# APM32F103xx register map
File version: 1.0
CPU: CM3 r2p1, little endian, no MPU, no FPU, 4 interrupt priority bits
Registers are 32-bit, read-write, reset 0x0 unless marked. A register's access mark holds for its fields unless they carry their own. Offsets are from the block's base; [hi:lo] are bit positions; lines under a group give offsets from that group; {n}, {i} and the like mark numbered series.

## ADC1 — Analog to digital converter
Base 0x40012400
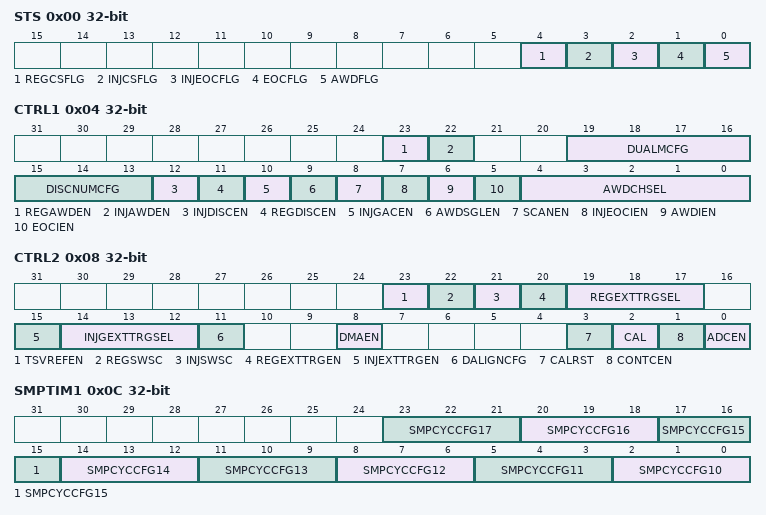
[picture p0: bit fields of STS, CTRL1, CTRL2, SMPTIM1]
0x00 STS — status register
  [4] REGCSFLG — Regular channel start flag
  [3] INJCSFLG — Injected channel start flag
  [2] INJEOCFLG — Injected channel end of conversion
  [1] EOCFLG — Regular channel end of conversion
  [0] AWDFLG — Analog watchdog flag
0x04 CTRL1 — control register 1
  [23] REGAWDEN — Analog watchdog enable on regular channels
  [22] INJAWDEN — Analog watchdog enable on injected channels
  [19:16] DUALMCFG — Dual mode selection
  [15:13] DISCNUMCFG — Discontinuous mode channel count
  [12] INJDISCEN — Discontinuous mode on injected channels
  [11] REGDISCEN — Discontinuous mode on regular channels
  [10] INJGACEN — Automatic injected group conversion
  [9] AWDSGLEN — Enable the watchdog on a single channel in scan mode
  [8] SCANEN — Scan mode
  [7] INJEOCIEN — Interrupt enable for injected channels
  [6] AWDIEN — Analog watchdog interrupt enable
  [5] EOCIEN — Interrupt enable for EOC
  [4:0] AWDCHSEL — Analog watchdog channel select bits
0x08 CTRL2 — control register 2
  [23] TSVREFEN — Temperature sensor and VREFINT enable
  [22] REGSWSC — Start conversion of regular channels
  [21] INJSWSC — Start conversion of injected channels
  [20] REGEXTTRGEN — External trigger conversion mode for regular channels
  [19:17] REGEXTTRGSEL — External event select for regular group
  [15] INJEXTTRGEN — External trigger conversion mode for injected channels
  [14:12] INJGEXTTRGSEL — External event select for injected group
  [11] DALIGNCFG — Data alignment
  [8] DMAEN — Direct memory access mode
  [3] CALRST — Reset calibration
  [2] CAL — A/D calibration
  [1] CONTCEN — Continuous conversion
  [0] ADCEN — A/D converter ON / OFF
0x0C SMPTIM1 — sample time register 1
  [3n-28:3n-30] SMPCYCCFG{n} (n=10..17) — Channel {n} sample time selection
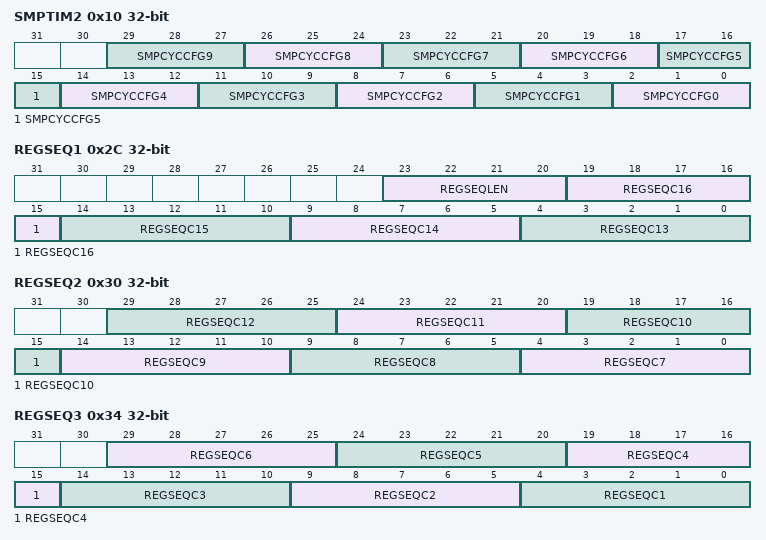
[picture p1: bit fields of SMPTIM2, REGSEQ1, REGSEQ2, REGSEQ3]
0x10 SMPTIM2 — sample time register 2
  [3n+2:3n] SMPCYCCFG{n} (n=0..9) — Channel {n} sample time selection
{0x10+4i} INJDOF{i} (i=1..4) — injected channel data offset register {i}
  [11:0] INJDOF{i} — Data offset for injected channel {i}
0x24 AWDHT reset 0xFFF — watchdog higher threshold register
  [11:0] AWDHT — Analog watchdog higher threshold
0x28 AWDLT — watchdog lower threshold register
  [11:0] AWDLT — Analog watchdog lower threshold
0x2C REGSEQ1 — regular sequence register 1
  [23:20] REGSEQLEN — Regular channel sequence length
  [5n-61:5n-65] REGSEQC{n} (n=13..16) — {n}th conversion in regular sequence
0x30 REGSEQ2 — regular sequence register 2
  [5n-31:5n-35] REGSEQC{n} (n=7..12) — {n}th conversion in regular sequence
0x34 REGSEQ3 — regular sequence register 3
  [29:25] REGSEQC6 — 6th conversion in regular sequence
  [24:20] REGSEQC5 — 5th conversion in regular sequence
  [19:15] REGSEQC4 — 4th conversion in regular sequence
  [14:10] REGSEQC3 — 3rd conversion in regular sequence
  [9:5] REGSEQC2 — 2nd conversion in regular sequence
  [4:0] REGSEQC1 — 1st conversion in regular sequence
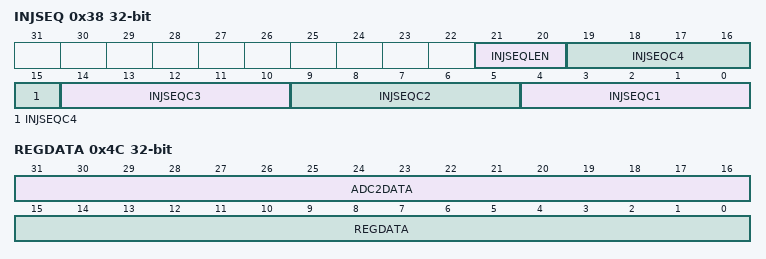
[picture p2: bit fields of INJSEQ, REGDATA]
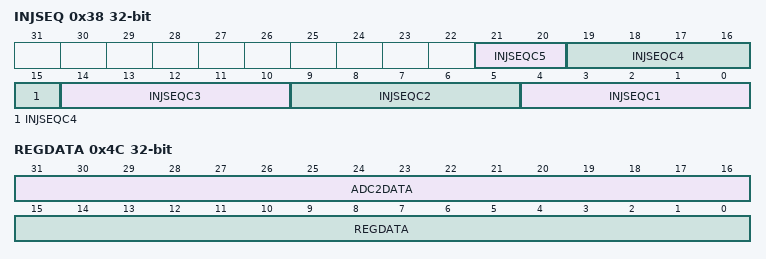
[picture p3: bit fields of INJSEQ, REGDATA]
0x38 INJSEQ — injected sequence register
  [21:20] INJSEQLEN — Injected sequence length
  [19:15] INJSEQC4 — 4th conversion in injected sequence
  [14:10] INJSEQC3 — 3rd conversion in injected sequence
  [9:5] INJSEQC2 — 2nd conversion in injected sequence
  [4:0] INJSEQC1 — 1st conversion in injected sequence
{0x38+4i} INJDATA{i} ro (i=1..4) — injected data register {i}
  [15:0] INJDATA — Injected data
0x4C REGDATA ro — regular data register
  [31:16] ADC2DATA
  [15:0] REGDATA — Regular data

## ADC2 — Analog to digital converter
Base 0x40012800
Same registers: ADC3 0x40013C00
Registers as ADC1; these are added or differ:
0x38 INJSEQ — injected sequence register
  [21:20] INJSEQC5 — Injected sequence length
  [19:15] INJSEQC4 — 4th conversion in injected sequence
  [14:10] INJSEQC3 — 3rd conversion in injected sequence
  [9:5] INJSEQC2 — 2nd conversion in injected sequence
  [4:0] INJSEQC1 — 1st conversion in injected sequence
0x4C REGDATA ro — regular data register
  [31:16] ADC2DATA
  [15:0] REGDATA — Regular data
